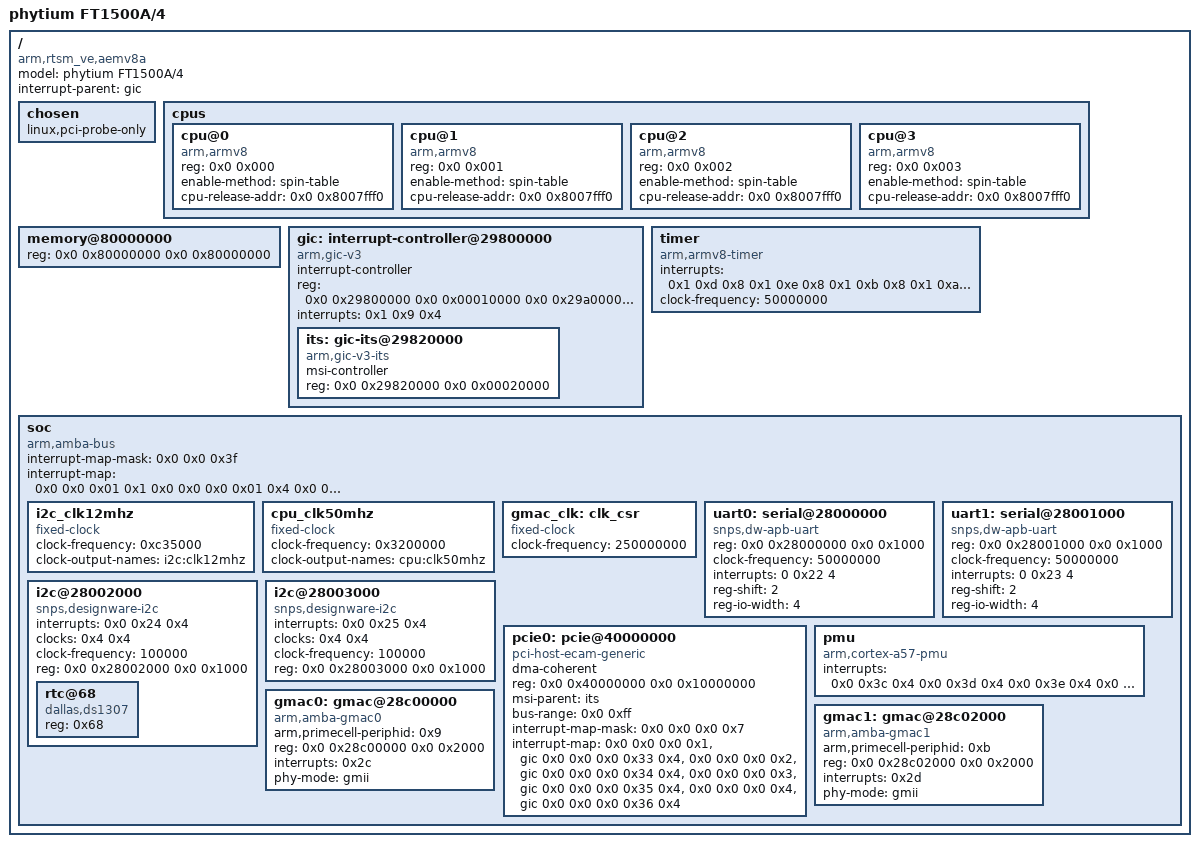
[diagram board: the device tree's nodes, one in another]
/*
 * DTS file for Phytium FT-1500A SoC
 *
 * Copyright (C) 2015, Phytium Technology Co., Ltd.
 *
 * This file is licensed under a dual GPLv2 or BSD license.
 */

/dts-v1/;

/memreserve/    0x80000000 0x100000;
/{
	model = "phytium FT1500A/4";
	compatible = "arm,rtsm_ve,aemv8a", "arm,vexpress";
	#address-cells = <0x2>;
	#size-cells = <0x2>;
	interrupt-parent = <&gic>;
	
	chosen {
		linux,pci-probe-only; 
	};
	
	cpus {
		#address-cells = <0x2>;
		#size-cells = <0x0>;

		 cpu@0 {
		 device_type = "cpu";
		 compatible = "arm,armv8";
		 reg = <0x0 0x000>;
		 enable-method = "spin-table";
		 cpu-release-addr = <0x0 0x8007fff0>;
		 };

		 cpu@1 {
		 device_type = "cpu";
		 compatible = "arm,armv8";
		 reg = <0x0 0x001>;
		 enable-method = "spin-table";
		 cpu-release-addr = <0x0 0x8007fff0>;
		 };

		 cpu@2 {
		 device_type = "cpu";
		 compatible = "arm,armv8";
		 reg = <0x0 0x002>;
		 enable-method = "spin-table";
		 cpu-release-addr = <0x0 0x8007fff0>;
		 };

		 cpu@3 {
		 device_type = "cpu";
		 compatible = "arm,armv8";
		 reg = <0x0 0x003>;
		 enable-method = "spin-table";
		 cpu-release-addr = <0x0 0x8007fff0>;
		 };

	};
	
	memory@80000000 {
		device_type = "memory";
		reg = <0x0 0x80000000 0x0 0x80000000>;
	};
	
	gic: interrupt-controller@29800000 {
		compatible = "arm,gic-v3";
		#interrupt-cells = <0x3>;
		#address-cells = <0x2>;
		#size-cells = <0x2>;
		ranges;
		interrupt-controller;
		/*regs are different from ft2000?*/
		reg = <0x0 0x29800000 0x0 0x00010000 
		       0x0 0x29a00000 0x0 0x00200000 
		       0x0 0x29c00000 0x0 0x00010000 
		       0x0 0x29c10000 0x0 0x00010000 
		       0x0 0x29c20000 0x0 0x00010000>;
		interrupts = <0x1 0x9 0x4>;
		linux,phandle = <0x1>;
		phandle = <0x1>;
		
		its: gic-its@29820000 {
			compatible = "arm,gic-v3-its";
			msi-controller;
			reg = <0x0 0x29820000 0x0 0x00020000>;
			linux,phandle = <0x2>;
			phandle = <0x2>;
		};
	};

	timer { /* drivers/clocksource/arm_arch_timer.c */
		/* CONFIG_ARM_ARCH_TIMER: 
			select CLKSRC_OF if OF
			select CLKSRC_ACPI if ACPI
		*/
		compatible = "arm,armv8-timer";
		interrupts = <0x1 0xd 0x8         /*13+16 = 29 PHYS_SECURE_PPI*/
				0x1 0xe 0x8       /*14+16 = 30 PHYS_NONSECURE_PPI*/
				0x1 0xb 0x8       /*11+16 = 27 VIRT_PPI*/
				0x1 0xa 0x8>;     /*10+16 = 26 HYP_PPI*/
		/*clock-frequency = <0x2faf080>;*/
		clock-frequency = <50000000>;
	};
	soc {
		compatible = "arm,amba-bus", "simple-bus";
		#address-cells = <0x2>;
		#size-cells = <0x2>;
		ranges;
		#interrupt-cells = <0x1>;
		interrupt-map-mask = <0x0 0x0 0x3f>;
		interrupt-map = <0x0 0x0 0x01 0x1 0x0 0x0 0x0 0x01 0x4 
						0x0 0x0 0x02 0x1 0x0 0x0 0x0 0x02 0x4  /**/
						0x0 0x0 0x03 0x1 0x0 0x0 0x0 0x03 0x4  /**/
						0x0 0x0 0x04 0x1 0x0 0x0 0x0 0x04 0x4  /**/
						0x0 0x0 0x05 0x1 0x0 0x0 0x0 0x05 0x4  /**/
						0x0 0x0 0x06 0x1 0x0 0x0 0x0 0x06 0x4  /**/
						0x0 0x0 0x07 0x1 0x0 0x0 0x0 0x07 0x4  /**/
						0x0 0x0 0x08 0x1 0x0 0x0 0x0 0x08 0x4  /**/
						0x0 0x0 0x09 0x1 0x0 0x0 0x0 0x09 0x4  /**/
						0x0 0x0 0x0a 0x1 0x0 0x0 0x0 0x0a 0x4  /**/
						0x0 0x0 0x0b 0x1 0x0 0x0 0x0 0x0b 0x4  /**/
						0x0 0x0 0x0c 0x1 0x0 0x0 0x0 0x0c 0x4  /**/
						0x0 0x0 0x0d 0x1 0x0 0x0 0x0 0x0d 0x4  /**/
						0x0 0x0 0x0e 0x1 0x0 0x0 0x0 0x0e 0x4  /**/
						0x0 0x0 0x0f 0x1 0x0 0x0 0x0 0x0f 0x4  /**/
						0x0 0x0 0x10 0x1 0x0 0x0 0x0 0x10 0x4  /**/
						0x0 0x0 0x11 0x1 0x0 0x0 0x0 0x11 0x4  /**/
						0x0 0x0 0x12 0x1 0x0 0x0 0x0 0x12 0x4  /**/
						0x0 0x0 0x13 0x1 0x0 0x0 0x0 0x13 0x4  /**/
						0x0 0x0 0x14 0x1 0x0 0x0 0x0 0x14 0x4  /**/
						0x0 0x0 0x15 0x1 0x0 0x0 0x0 0x15 0x4  /**/
						0x0 0x0 0x16 0x1 0x0 0x0 0x0 0x16 0x4  /**/
						0x0 0x0 0x17 0x1 0x0 0x0 0x0 0x17 0x4  /**/
						0x0 0x0 0x18 0x1 0x0 0x0 0x0 0x18 0x4  /**/
						0x0 0x0 0x19 0x1 0x0 0x0 0x0 0x19 0x4  /**/
						0x0 0x0 0x1a 0x1 0x0 0x0 0x0 0x1a 0x4  /**/
						0x0 0x0 0x1b 0x1 0x0 0x0 0x0 0x1b 0x4  /**/
						0x0 0x0 0x1c 0x1 0x0 0x0 0x0 0x1c 0x4  
						0x0 0x0 0x1d 0x1 0x0 0x0 0x0 0x1d 0x4  
						0x0 0x0 0x1e 0x1 0x0 0x0 0x0 0x1e 0x4  
						0x0 0x0 0x1f 0x1 0x0 0x0 0x0 0x1f 0x4  
						0x0 0x0 0x20 0x1 0x0 0x0 0x0 0x20 0x4  
						0x0 0x0 0x21 0x1 0x0 0x0 0x0 0x21 0x4  /*33+32=65 lpc*/
						0x0 0x0 0x22 0x1 0x0 0x0 0x0 0x22 0x4  /*34+32=66 uart@28000000*/
						0x0 0x0 0x23 0x1 0x0 0x0 0x0 0x23 0x4  /*35+32=67 uart@28001000*/
						0x0 0x0 0x24 0x1 0x0 0x0 0x0 0x24 0x4  /*36+32=68 i2c@28002000*/
						0x0 0x0 0x25 0x1 0x0 0x0 0x0 0x25 0x4  /*37+32=69 i2c@28003000*/
						0x0 0x0 0x26 0x1 0x0 0x0 0x0 0x26 0x4  /*38+32=70 wdt*/
						0x0 0x0 0x27 0x1 0x0 0x0 0x0 0x27 0x4  /*39+32=71 wdt*/
						0x0 0x0 0x28 0x1 0x0 0x0 0x0 0x28 0x4 
						0x0 0x0 0x29 0x1 0x0 0x0 0x0 0x29 0x4 
						0x0 0x0 0x2a 0x1 0x0 0x0 0x0 0x2a 0x4 
						0x0 0x0 0x2b 0x1 0x0 0x0 0x0 0x2b 0x4 
						0x0 0x0 0x2c 0x1 0x0 0x0 0x0 0x2c 0x4   /*44+32=76 gmac@28c00000*/
						0x0 0x0 0x2d 0x1 0x0 0x0 0x0 0x2d 0x4>; /*45+32=77 gmac@28c02000*/
	
		i2c_clk12mhz { /*drivers/clk/clk-fixed-rate.c */
			/* CONFIG_COMMON_CLK */
			compatible = "fixed-clock";
			#clock-cells = <0x0>;
			/*	clock-frequency = <0x1c2000>; */
			clock-frequency = <0xc35000>;   	/* 12MHz*/
			clock-output-names = "i2c:clk12mhz";
			linux,phandle = <0x4>;
			phandle = <0x4>;
		};

		cpu_clk50mhz { /*drivers/clk/clk-fixed-rate.c */
			/* CONFIG_COMMON_CLK */
			compatible = "fixed-clock";
			#clock-cells = <0x0>;
			clock-frequency = <0x3200000>;   	/* 50MHz*/
			clock-output-names = "cpu:clk50mhz";
			linux,phandle = <0x5>;
			phandle = <0x5>;
		};
		
		gmac_clk: clk_csr {
			compatible = "fixed-clock";
			#clock-cells = <0>;
			clock-frequency = <250000000>;
		};
		
		uart0: serial@28000000 {
			compatible = "snps,dw-apb-uart";
			reg = <0x0 0x28000000 0x0 0x1000>;
			clock-frequency = <50000000>;
			interrupts = <0 0x22 4>;
			reg-shift = <2>;
			reg-io-width = <4>;
		};

		uart1: serial@28001000 {
			compatible = "snps,dw-apb-uart";
			reg = <0x0 0x28001000 0x0 0x1000>;
			clock-frequency = <50000000>;
			interrupts = <0 0x23 4>;
			reg-shift = <2>;
			reg-io-width = <4>;
		};
		
		i2c@28002000 {
			compatible = "snps,designware-i2c";
			#address-cells = <0x1>;
			#size-cells = <0>;
			interrupts = <0x0 0x24 0x4>;
			clocks = <0x4 0x4>;
			clock-frequency = <100000>;
			reg = <0x0 0x28002000 0x0 0x1000>;

			rtc@68 {
			/*	compatible = "dallas,ds1339";*/
				compatible = "dallas,ds1307";
				reg = <0x68>;
			};
		};
		
		i2c@28003000 {
			compatible = "snps,designware-i2c";
			#address-cells = <0x2>;
			#size-cells = <0x2>;
			interrupts = <0x0 0x25 0x4>;
			clocks = <0x4 0x4>;
			clock-frequency = <100000>;
			reg = <0x0 0x28003000 0x0 0x1000>;
		};
		
		/*need to be backported from ft2000?*/
		/*
		gpio@28006000 {
			compatible = "arm,platform-gpio";
			reg = <0x0 0x28006000 0x0 0x80>;
		};
		*/
		
		pcie0: pcie@40000000{
			compatible = "pci-host-ecam-generic";
			device_type = "pci";
			#address-cells = <0x3>;
			#size-cells = <0x2>;
			#interrupt-cells = <0x1>;
			dma-coherent;
			reg = <0x0 0x40000000 0x0 0x10000000>;
			msi-parent = <&its>;
			bus-range = <0x0 0xff>;
			interrupt-map-mask = <0x0 0x0 0x0 0x7>;
			interrupt-map = <0x0 0x0 0x0 0x1 &gic 0x0 0x0 0x0 0x33 0x4>,
							<0x0 0x0 0x0 0x2 &gic 0x0 0x0 0x0 0x34 0x4>,
							<0x0 0x0 0x0 0x3 &gic 0x0 0x0 0x0 0x35 0x4>,
							<0x0 0x0 0x0 0x4 &gic 0x0 0x0 0x0 0x36 0x4>;
			ranges = <0x01000000 0x00 0x00000000 0x00 0x50000000 0x00 0x01000000>,
					 <0x02000000 0x00 0x60000000 0x00 0x60000000 0x00 0x20000000>,
					 <0x03000000 0x01 0x00000000 0x01 0x00000000 0x01 0x00000000>;
		};

		pmu {
			compatible = "arm,cortex-a57-pmu";
			interrupts = <0x0 0x3c 0x4 
						  0x0 0x3d 0x4 
						  0x0 0x3e 0x4 
						  0x0 0x3f 0x4>;
		};

		gmac0:gmac@28c00000 {
			compatible = "arm,amba-gmac0", "arm,primecell";
			arm,primecell-periphid = <0x9>;
			reg = <0x0 0x28c00000 0x0 0x2000>;
			interrupts = <0x2c>;
			status = "disable";
		};
		gmac1:gmac@28c02000 {
			compatible = "arm,amba-gmac1", "arm,primecell";
			arm,primecell-periphid = <0xb>;
			reg = <0x0 0x28c02000 0x0 0x2000>;
			interrupts = <0x2d>;
			status = "disable";
		};
	};
};

&uart0 {
	status = "ok";
};
&gmac0 {
	phy-mode = "gmii";
	status = "ok";
};
&gmac1 {
	phy-mode = "gmii";
	status = "ok";
};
